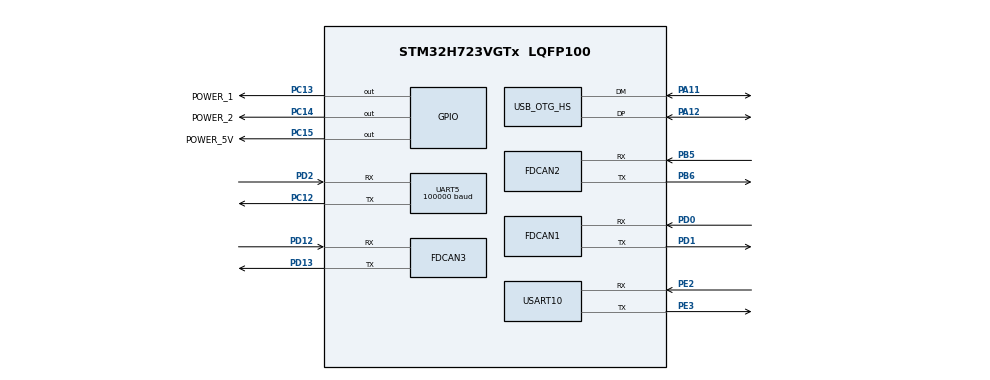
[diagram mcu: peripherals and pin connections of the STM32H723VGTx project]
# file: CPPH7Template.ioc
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CORTEX_M7.AccessPermission_S-Cortex_Memory_Protection_Unit_Region1_Settings_S=MPU_REGION_FULL_ACCESS
CORTEX_M7.AccessPermission_Spec=MPU_REGION_FULL_ACCESS
CORTEX_M7.BaseAddress_S-Cortex_Memory_Protection_Unit_Region1_Settings_S=0x80000000
CORTEX_M7.BaseAddress_Spec=0x24000000
CORTEX_M7.CPU_DCache=Enabled
CORTEX_M7.CPU_ICache=Enabled
CORTEX_M7.DisableExec_Spec=MPU_INSTRUCTION_ACCESS_ENABLE
CORTEX_M7.Enable_S-Cortex_Memory_Protection_Unit_Region1_Settings_S=MPU_REGION_ENABLE
CORTEX_M7.IsShareable_Spec=MPU_ACCESS_NOT_SHAREABLE
CORTEX_M7.Size_S-Cortex_Memory_Protection_Unit_Region1_Settings_S=MPU_REGION_SIZE_1MB
CORTEX_M7.Size_Spec=MPU_REGION_SIZE_256KB
CORTEX_M7.SubRegionDisable_Spec=0x0
CORTEX_M7.default_mode_Activation=1
Dma.Request0=UART5_RX
Dma.UART5_RX.0.Direction=DMA_PERIPH_TO_MEMORY
Dma.UART5_RX.0.EventEnable=DISABLE
Dma.UART5_RX.0.FIFOMode=DMA_FIFOMODE_DISABLE
Dma.UART5_RX.0.Instance=DMA2_Stream3
Dma.UART5_RX.0.MemDataAlignment=DMA_MDATAALIGN_BYTE
Dma.UART5_RX.0.MemInc=DMA_MINC_ENABLE
Dma.UART5_RX.0.Mode=DMA_CIRCULAR
Dma.UART5_RX.0.PeriphDataAlignment=DMA_PDATAALIGN_BYTE
Dma.UART5_RX.0.PeriphInc=DMA_PINC_DISABLE
Dma.UART5_RX.0.Polarity=HAL_DMAMUX_REQ_GEN_RISING
Dma.UART5_RX.0.Priority=DMA_PRIORITY_VERY_HIGH
Dma.UART5_RX.0.RequestNumber=1
Dma.UART5_RX.0.SignalID=NONE
Dma.UART5_RX.0.SyncEnable=DISABLE
Dma.UART5_RX.0.SyncPolarity=HAL_DMAMUX_SYNC_NO_EVENT
Dma.UART5_RX.0.SyncRequestNumber=1
Dma.UART5_RX.0.SyncSignalID=NONE
FDCAN1.AutoRetransmission=ENABLE
FDCAN1.CalculateBaudRateNominal=1000000
FDCAN1.CalculateTimeBitNominal=1000
FDCAN1.CalculateTimeQuantumNominal=50.0
FDCAN1.DataPrescaler=5
FDCAN1.DataSyncJumpWidth=5
FDCAN1.DataTimeSeg1=14
FDCAN1.DataTimeSeg2=5
FDCAN1.NominalPrescaler=5
FDCAN1.NominalSyncJumpWidth=5
FDCAN1.NominalTimeSeg1=14
FDCAN1.NominalTimeSeg2=5
FDCAN1.ProtocolException=ENABLE
FDCAN1.RxFifo0ElmtsNbr=8
FDCAN1.StdFiltersNbr=1
FDCAN1.TxFifoQueueElmtsNbr=8
FDCAN2.AutoRetransmission=ENABLE
FDCAN2.CalculateBaudRateNominal=1000000
FDCAN2.CalculateTimeBitNominal=1000
FDCAN2.CalculateTimeQuantumNominal=50.0
FDCAN2.DataPrescaler=5
FDCAN2.DataSyncJumpWidth=5
FDCAN2.DataTimeSeg1=14
FDCAN2.DataTimeSeg2=5
FDCAN2.MessageRAMOffset=853
FDCAN2.NominalPrescaler=5
FDCAN2.NominalSyncJumpWidth=5
FDCAN2.NominalTimeSeg1=14
FDCAN2.NominalTimeSeg2=5
FDCAN2.ProtocolException=ENABLE
FDCAN2.RxFifo0ElmtsNbr=8
FDCAN2.RxFifo1ElmtsNbr=0
FDCAN2.StdFiltersNbr=1
FDCAN2.TxFifoQueueElmtsNbr=8
FDCAN3.AutoRetransmission=ENABLE
FDCAN3.CalculateBaudRateNominal=1000000
FDCAN3.CalculateTimeBitNominal=1000
FDCAN3.CalculateTimeQuantumNominal=50.0
FDCAN3.DataPrescaler=5
FDCAN3.DataSyncJumpWidth=5
FDCAN3.DataTimeSeg1=14
FDCAN3.DataTimeSeg2=5
FDCAN3.MessageRAMOffset=1706
FDCAN3.NominalPrescaler=5
FDCAN3.NominalSyncJumpWidth=5
FDCAN3.NominalTimeSeg1=14
FDCAN3.NominalTimeSeg2=5
FDCAN3.ProtocolException=ENABLE
FDCAN3.RxFifo0ElmtsNbr=8
FDCAN3.StdFiltersNbr=1
FDCAN3.TxFifoQueueElmtsNbr=8
FREERTOS.HEAP_NUMBER=5
FREERTOS.Mutexes01=RoboticAlgMutex,Dynamic,NULL,Available
FREERTOS.Tasks01=DebugTask,32,1024,App_DebugTask,As weak,NULL,Dynamic,NULL,NULL;RobiticsAlgTask,31,4096,App_RobiticsAlgTask,As external,NULL,Static,RobiticsAlgTaskBuffer,RobiticsAlgTaskControlBlock;Chassis_Task,32,1024,App_ChassisTask,As external,NULL,Dynamic,NULL,NULL
FREERTOS.configCHECK_FOR_STACK_OVERFLOW=2
FREERTOS.configENABLE_FPU=1
FREERTOS.configMAX_TASK_NAME_LEN=32
FREERTOS.configMINIMAL_STACK_SIZE=1024
FREERTOS.configTIMER_TASK_PRIORITY=3
FREERTOS.configTOTAL_HEAP_SIZE=12800
Mcu.Family=STM32H7
Mcu.Name=STM32H723VGTx
Mcu.Package=LQFP100
NVIC.DMA2_Stream3_IRQn=true\:5\:0\:false\:false\:true\:true\:false\:true\:true
NVIC.FDCAN1_IT0_IRQn=true\:5\:0\:false\:false\:true\:true\:true\:true\:true
NVIC.FDCAN2_IT0_IRQn=true\:5\:0\:false\:false\:true\:true\:true\:true\:true
NVIC.FDCAN3_IT0_IRQn=true\:5\:0\:false\:false\:true\:true\:true\:true\:true
NVIC.OTG_HS_IRQn=true\:5\:0\:false\:false\:true\:true\:true\:true\:true
NVIC.PriorityGroup=NVIC_PRIORITYGROUP_4
NVIC.TIM2_IRQn=true\:15\:0\:false\:false\:true\:false\:false\:true\:true
NVIC.TimeBase=TIM2_IRQn
NVIC.TimeBaseIP=TIM2
NVIC.UART5_IRQn=true\:5\:0\:false\:false\:true\:true\:true\:true\:true
PA11.Mode=Device_Only_FS
PA11.Signal=USB_OTG_HS_DM
PA12.Mode=Device_Only_FS
PA12.Signal=USB_OTG_HS_DP
PA13(JTMS/SWDIO).Mode=Serial_Wire
PA13(JTMS/SWDIO).Signal=DEBUG_JTMS-SWDIO
PA14(JTCK/SWCLK).Mode=Serial_Wire
PA14(JTCK/SWCLK).Signal=DEBUG_JTCK-SWCLK
PB5.Mode=FDCAN_Activate
PB5.Signal=FDCAN2_RX
PB6.Mode=FDCAN_Activate
PB6.Signal=FDCAN2_TX
PC12.Mode=Asynchronous
PC12.Signal=UART5_TX
PC13.GPIO_Label=POWER_1
PC13.PinState=GPIO_PIN_SET
PC13.Signal=GPIO_Output
PC14-OSC32_IN.GPIO_Label=POWER_2
PC14-OSC32_IN.PinState=GPIO_PIN_SET
PC14-OSC32_IN.Signal=GPIO_Output
PC15-OSC32_OUT.GPIO_Label=POWER_5V
PC15-OSC32_OUT.PinState=GPIO_PIN_SET
PC15-OSC32_OUT.Signal=GPIO_Output
PD0.Mode=FDCAN_Activate
PD0.Signal=FDCAN1_RX
PD1.Mode=FDCAN_Activate
PD1.Signal=FDCAN1_TX
PD12.Mode=FDCAN_Activate
PD12.Signal=FDCAN3_RX
PD13.Mode=FDCAN_Activate
PD13.Signal=FDCAN3_TX
PD2.GPIO_Speed=GPIO_SPEED_FREQ_VERY_HIGH
PD2.Mode=Asynchronous
PD2.Signal=UART5_RX
PE2.Mode=Asynchronous
PE2.Signal=USART10_RX
PE3.Mode=Asynchronous
PE3.Signal=USART10_TX
PH0-OSC_IN.Mode=HSE-External-Oscillator
PH0-OSC_IN.Signal=RCC_OSC_IN
PH1-OSC_OUT.Mode=HSE-External-Oscillator
PH1-OSC_OUT.Signal=RCC_OSC_OUT
ProjectManager.HeapSize=0x2000
ProjectManager.StackSize=0x4000
ProjectManager.TargetToolchain=CMake
RCC.ADCFreq_Value=100000000
RCC.APB1Freq_Value=80000000
RCC.APB2Freq_Value=80000000
RCC.APB3Freq_Value=80000000
RCC.APB4Freq_Value=80000000
RCC.CortexFreq_Value=640000000
RCC.D1PPRE=RCC_APB3_DIV2
RCC.D2PPRE1=RCC_APB1_DIV2
RCC.D2PPRE2=RCC_APB2_DIV2
RCC.D3PPRE=RCC_APB4_DIV2
RCC.DIVM1=6
RCC.DIVM2=24
RCC.DIVM3=24
RCC.DIVN1=160
RCC.DIVN2=200
RCC.DIVN3=160
RCC.DIVP1=1
RCC.DIVQ1=4
RCC.FDCANCLockSelection=RCC_FDCANCLKSOURCE_PLL2
RCC.HCLKFreq_Value=160000000
RCC.HPRE=RCC_HCLK_DIV4
RCC.HSE_VALUE=24000000
RCC.PLLSourceVirtual=RCC_PLLSOURCE_HSE
RCC.SYSCLKFreq_VALUE=640000000
RCC.SYSCLKSource=RCC_SYSCLKSOURCE_PLLCLK
RCC.USART16CLockSelection=RCC_USART16910CLKSOURCE_PLL2
RCC.USBCLockSelection=RCC_USBCLKSOURCE_HSI48
RCC.USBFreq_Value=48000000
STMicroelectronics.X-CUBE-ALGOBUILD.1.4.0.LibraryCcDSPOoLibraryJjDSPOoLibrary=true
UART5.BaudRate=100000
UART5.Parity=PARITY_EVEN
UART5.StopBits=UART_STOPBITS_2
UART5.WordLength=WORDLENGTH_9B
USART10.VirtualMode=VM_ASYNC
USB_DEVICE.CLASS_NAME_HS=CDC
USB_DEVICE.VirtualMode=Cdc
USB_DEVICE.VirtualModeHS=Cdc_HS
USB_OTG_HS.VirtualMode-Device_Only_FS=Device_Only_FS
VP_FREERTOS_VS_CMSIS_V2.Mode=CMSIS_V2
VP_MEMORYMAP_VS_MEMORYMAP.Mode=CurAppReg
VP_STMicroelectronics.X-CUBE-ALGOBUILD_VS_DSPOoLibraryJjLibrary_1.4.0_1.4.0.Mode=DSPOoLibraryJjLibrary
VP_SYS_VS_tim2.Mode=TIM2
VP_USB_DEVICE_VS_USB_DEVICE_CDC_HS.Mode=CDC_HS
board=custom

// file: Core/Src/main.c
/* USER CODE BEGIN Header */
/**
  ******************************************************************************
  * @file           : main.c
  * @brief          : Main program body
  ******************************************************************************
  * @attention
  *
  * Copyright (c) 2025 STMicroelectronics.
  * All rights reserved.
  *
  * This software is licensed under terms that can be found in the LICENSE file
  * in the root directory of this software component.
  * If no LICENSE file comes with this software, it is provided AS-IS.
  *
  ******************************************************************************
  */
/* USER CODE END Header */
#include "main.h"
#include "cmsis_os.h"
#include "dma.h"
#include "fdcan.h"
#include "usart.h"
#include "usb_device.h"
#include "gpio.h"

/* USER CODE BEGIN Includes */
#include "globalInit.h"
/* USER CODE END Includes */

void SystemClock_Config(void);
void PeriphCommonClock_Config(void);
static void MPU_Config(void);
void MX_FREERTOS_Init(void);

int main(void)
{

  /* USER CODE BEGIN 1 */
  SCB->CCR &= ~(SCB_CCR_UNALIGN_TRP_Msk);   /* 清 0，关闭非对齐报错 */
  __DSB();                                  /* 保证配置生效 */
  __ISB();
  /* USER CODE END 1 */

  /* MPU Configuration--------------------------------------------------------*/
  MPU_Config();

  /* Enable the CPU Cache */

  /* Enable I-Cache---------------------------------------------------------*/
  SCB_EnableICache();

  /* Enable D-Cache---------------------------------------------------------*/
  SCB_EnableDCache();

  /* MCU Configuration--------------------------------------------------------*/

  /* Reset of all peripherals, Initializes the Flash interface and the Systick. */
  HAL_Init();

  /* Configure the system clock */
  SystemClock_Config();

  /* Configure the peripherals common clocks */
  PeriphCommonClock_Config();

  /* Initialize all configured peripherals */
  MX_GPIO_Init();
  MX_DMA_Init();
  MX_FDCAN1_Init();
  MX_FDCAN2_Init();
  MX_FDCAN3_Init();
  MX_UART5_Init();
  MX_USART10_UART_Init();
  /* USER CODE BEGIN 2 */
  Global_Init();
  /* USER CODE END 2 */

  /* Init scheduler */
  osKernelInitialize();  /* Call init function for freertos objects (in cmsis_os2.c) */
  MX_FREERTOS_Init();

  /* Start scheduler */
  osKernelStart();

  /* We should never get here as control is now taken by the scheduler */

  /* Infinite loop */
  while (1)
  {

  }
}

void SystemClock_Config(void)
{
  RCC_OscInitTypeDef RCC_OscInitStruct = {0};
  RCC_ClkInitTypeDef RCC_ClkInitStruct = {0};

  /** Supply configuration update enable
  */
  HAL_PWREx_ConfigSupply(PWR_LDO_SUPPLY);

  /** Configure the main internal regulator output voltage
  */
  __HAL_PWR_VOLTAGESCALING_CONFIG(PWR_REGULATOR_VOLTAGE_SCALE1);

  while(!__HAL_PWR_GET_FLAG(PWR_FLAG_VOSRDY)) {}

  /** Initializes the RCC Oscillators according to the specified parameters
  * in the RCC_OscInitTypeDef structure.
  */
  RCC_OscInitStruct.OscillatorType = RCC_OSCILLATORTYPE_HSI48|RCC_OSCILLATORTYPE_HSE;
  RCC_OscInitStruct.HSEState = RCC_HSE_ON;
  RCC_OscInitStruct.HSI48State = RCC_HSI48_ON;
  RCC_OscInitStruct.PLL.PLLState = RCC_PLL_ON;
  RCC_OscInitStruct.PLL.PLLSource = RCC_PLLSOURCE_HSE;
  RCC_OscInitStruct.PLL.PLLM = 6;
  RCC_OscInitStruct.PLL.PLLN = 160;
  RCC_OscInitStruct.PLL.PLLP = 1;
  RCC_OscInitStruct.PLL.PLLQ = 4;
  RCC_OscInitStruct.PLL.PLLR = 2;
  RCC_OscInitStruct.PLL.PLLRGE = RCC_PLL1VCIRANGE_2;
  RCC_OscInitStruct.PLL.PLLVCOSEL = RCC_PLL1VCOWIDE;
  RCC_OscInitStruct.PLL.PLLFRACN = 0;
  if (HAL_RCC_OscConfig(&RCC_OscInitStruct) != HAL_OK)
  {
    Error_Handler();
  }

  /** Initializes the CPU, AHB and APB buses clocks
  */
  RCC_ClkInitStruct.ClockType = RCC_CLOCKTYPE_HCLK|RCC_CLOCKTYPE_SYSCLK
                              |RCC_CLOCKTYPE_PCLK1|RCC_CLOCKTYPE_PCLK2
                              |RCC_CLOCKTYPE_D3PCLK1|RCC_CLOCKTYPE_D1PCLK1;
  RCC_ClkInitStruct.SYSCLKSource = RCC_SYSCLKSOURCE_PLLCLK;
  RCC_ClkInitStruct.SYSCLKDivider = RCC_SYSCLK_DIV1;
  RCC_ClkInitStruct.AHBCLKDivider = RCC_HCLK_DIV4;
  RCC_ClkInitStruct.APB3CLKDivider = RCC_APB3_DIV2;
  RCC_ClkInitStruct.APB1CLKDivider = RCC_APB1_DIV2;
  RCC_ClkInitStruct.APB2CLKDivider = RCC_APB2_DIV2;
  RCC_ClkInitStruct.APB4CLKDivider = RCC_APB4_DIV2;

  if (HAL_RCC_ClockConfig(&RCC_ClkInitStruct, FLASH_LATENCY_2) != HAL_OK)
  {
    Error_Handler();
  }
}

void PeriphCommonClock_Config(void)
{
  RCC_PeriphCLKInitTypeDef PeriphClkInitStruct = {0};

  /** Initializes the peripherals clock
  */
  PeriphClkInitStruct.PeriphClockSelection = RCC_PERIPHCLK_FDCAN|RCC_PERIPHCLK_USART10;
  PeriphClkInitStruct.PLL2.PLL2M = 24;
  PeriphClkInitStruct.PLL2.PLL2N = 200;
  PeriphClkInitStruct.PLL2.PLL2P = 2;
  PeriphClkInitStruct.PLL2.PLL2Q = 2;
  PeriphClkInitStruct.PLL2.PLL2R = 2;
  PeriphClkInitStruct.PLL2.PLL2RGE = RCC_PLL2VCIRANGE_0;
  PeriphClkInitStruct.PLL2.PLL2VCOSEL = RCC_PLL2VCOMEDIUM;
  PeriphClkInitStruct.PLL2.PLL2FRACN = 0;
  PeriphClkInitStruct.FdcanClockSelection = RCC_FDCANCLKSOURCE_PLL2;
  PeriphClkInitStruct.Usart16ClockSelection = RCC_USART16910CLKSOURCE_PLL2;
  if (HAL_RCCEx_PeriphCLKConfig(&PeriphClkInitStruct) != HAL_OK)
  {
    Error_Handler();
  }
}

 /* MPU Configuration */

void MPU_Config(void)
{
  MPU_Region_InitTypeDef MPU_InitStruct = {0};

  /* Disables the MPU */
  HAL_MPU_Disable();

  /** Initializes and configures the Region and the memory to be protected
  */
  MPU_InitStruct.Enable = MPU_REGION_ENABLE;
  MPU_InitStruct.Number = MPU_REGION_NUMBER0;
  MPU_InitStruct.BaseAddress = 0x24000000;
  MPU_InitStruct.Size = MPU_REGION_SIZE_256KB;
  MPU_InitStruct.SubRegionDisable = 0x0;
  MPU_InitStruct.TypeExtField = MPU_TEX_LEVEL0;
  MPU_InitStruct.AccessPermission = MPU_REGION_FULL_ACCESS;
  MPU_InitStruct.DisableExec = MPU_INSTRUCTION_ACCESS_ENABLE;
  MPU_InitStruct.IsShareable = MPU_ACCESS_NOT_SHAREABLE;
  MPU_InitStruct.IsCacheable = MPU_ACCESS_NOT_CACHEABLE;
  MPU_InitStruct.IsBufferable = MPU_ACCESS_NOT_BUFFERABLE;

  HAL_MPU_ConfigRegion(&MPU_InitStruct);

  /** Initializes and configures the Region and the memory to be protected
  */
  MPU_InitStruct.Number = MPU_REGION_NUMBER1;
  MPU_InitStruct.BaseAddress = 0x80000000;
  MPU_InitStruct.Size = MPU_REGION_SIZE_1MB;

  HAL_MPU_ConfigRegion(&MPU_InitStruct);
  /* Enables the MPU */
  HAL_MPU_Enable(MPU_PRIVILEGED_DEFAULT);

}

void HAL_TIM_PeriodElapsedCallback(TIM_HandleTypeDef *htim)
{
  if (htim->Instance == TIM2)
  {
    HAL_IncTick();
  }
}

void Error_Handler(void)
{
  __disable_irq();
  while (1)
  {
  }
}

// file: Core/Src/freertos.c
/* USER CODE BEGIN Header */
/**
  ******************************************************************************
  * File Name          : freertos.c
  * Description        : Code for freertos applications
  ******************************************************************************
  * @attention
  *
  * Copyright (c) 2025 STMicroelectronics.
  * All rights reserved.
  *
  * This software is licensed under terms that can be found in the LICENSE file
  * in the root directory of this software component.
  * If no LICENSE file comes with this software, it is provided AS-IS.
  *
  ******************************************************************************
  */
/* USER CODE END Header */

#include "FreeRTOS.h"
#include "task.h"
#include "main.h"
#include "cmsis_os.h"

typedef StaticTask_t osStaticThreadDef_t;

/* USER CODE BEGIN Variables */
extern uint32_t user_stack[ 2048 ];
/* USER CODE END Variables */
/* Definitions for DebugTask */
osThreadId_t DebugTaskHandle;
const osThreadAttr_t DebugTask_attributes = {
  .name = "DebugTask",
  .stack_size = 1024 * 4,
  .priority = (osPriority_t) osPriorityAboveNormal,
};
/* Definitions for RobiticsAlgTask */
osThreadId_t RobiticsAlgTaskHandle;
uint32_t RobiticsAlgTaskBuffer[ 4096 ];
osStaticThreadDef_t RobiticsAlgTaskControlBlock;
const osThreadAttr_t RobiticsAlgTask_attributes = {
  .name = "RobiticsAlgTask",
  .cb_mem = &RobiticsAlgTaskControlBlock,
  .cb_size = sizeof(RobiticsAlgTaskControlBlock),
  .stack_mem = &RobiticsAlgTaskBuffer[0],
  .stack_size = sizeof(RobiticsAlgTaskBuffer),
  .priority = (osPriority_t) osPriorityNormal7,
};
/* Definitions for Chassis_Task */
osThreadId_t Chassis_TaskHandle;
const osThreadAttr_t Chassis_Task_attributes = {
  .name = "Chassis_Task",
  .stack_size = 1024 * 4,
  .priority = (osPriority_t) osPriorityAboveNormal,
};
/* Definitions for RoboticAlgMutex */
osMutexId_t RoboticAlgMutexHandle;
const osMutexAttr_t RoboticAlgMutex_attributes = {
  .name = "RoboticAlgMutex"
};

void App_DebugTask(void *argument);
extern void App_RobiticsAlgTask(void *argument);
extern void App_ChassisTask(void *argument);

extern void MX_USB_DEVICE_Init(void);
void MX_FREERTOS_Init(void); /* (MISRA C 2004 rule 8.1) */

/* Hook prototypes */
void vApplicationStackOverflowHook(xTaskHandle xTask, signed char *pcTaskName);

/* USER CODE BEGIN 4 */
void vApplicationStackOverflowHook(xTaskHandle xTask, signed char *pcTaskName)
{
   /* Run time stack overflow checking is performed if
   configCHECK_FOR_STACK_OVERFLOW is defined to 1 or 2. This hook function is
   called if a stack overflow is detected. */
}
/* USER CODE END 4 */

void MX_FREERTOS_Init(void) {
  /* USER CODE BEGIN Init */
  osThreadAttr_t RobiticsAlgTask_attributes = {
    .name = "RobiticsAlgTask",
    .cb_mem = &RobiticsAlgTaskControlBlock,
    .cb_size = sizeof(RobiticsAlgTaskControlBlock),
    .stack_mem = user_stack,
    .stack_size = sizeof(RobiticsAlgTaskBuffer),
    .priority = (osPriority_t) osPriorityAboveNormal1,
  };
  /* USER CODE END Init */
  /* Create the mutex(es) */
  /* creation of RoboticAlgMutex */
  RoboticAlgMutexHandle = osMutexNew(&RoboticAlgMutex_attributes);

  /* Create the thread(s) */
  /* creation of DebugTask */
  DebugTaskHandle = osThreadNew(App_DebugTask, NULL, &DebugTask_attributes);

  /* creation of RobiticsAlgTask */
  RobiticsAlgTaskHandle = osThreadNew(App_RobiticsAlgTask, NULL, &RobiticsAlgTask_attributes);

  /* creation of Chassis_Task */
  Chassis_TaskHandle = osThreadNew(App_ChassisTask, NULL, &Chassis_Task_attributes);

}

__weak void App_DebugTask(void *argument)
{
  /* init code for USB_DEVICE */
  MX_USB_DEVICE_Init();
  for(;;)
  {
    osDelay(1);
  }
}
